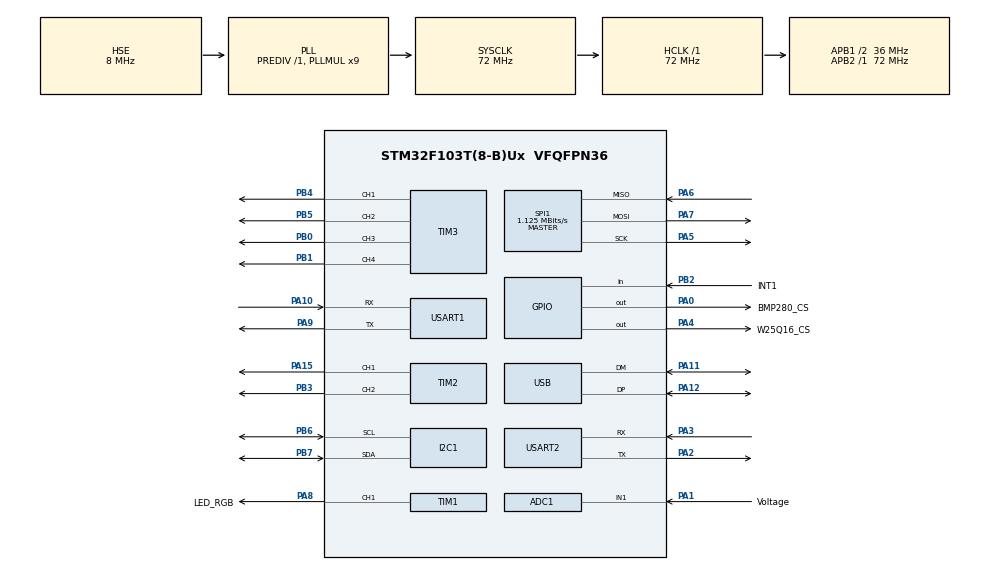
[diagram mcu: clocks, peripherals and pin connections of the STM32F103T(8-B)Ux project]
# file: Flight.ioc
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ADC1.Channel-1\#ChannelRegularConversion=ADC_CHANNEL_1
ADC1.NbrOfConversionFlag=1
ADC1.Rank-1\#ChannelRegularConversion=1
ADC1.SamplingTime-1\#ChannelRegularConversion=ADC_SAMPLETIME_1CYCLE_5
ADC1.master=1
Dma.Request0=TIM1_CH1
Dma.Request1=USART1_TX
Dma.TIM1_CH1.0.Direction=DMA_MEMORY_TO_PERIPH
Dma.TIM1_CH1.0.Instance=DMA1_Channel2
Dma.TIM1_CH1.0.MemDataAlignment=DMA_MDATAALIGN_HALFWORD
Dma.TIM1_CH1.0.MemInc=DMA_MINC_ENABLE
Dma.TIM1_CH1.0.Mode=DMA_NORMAL
Dma.TIM1_CH1.0.PeriphDataAlignment=DMA_PDATAALIGN_HALFWORD
Dma.TIM1_CH1.0.PeriphInc=DMA_PINC_DISABLE
Dma.TIM1_CH1.0.Priority=DMA_PRIORITY_VERY_HIGH
Dma.USART1_TX.1.Direction=DMA_MEMORY_TO_PERIPH
Dma.USART1_TX.1.Instance=DMA1_Channel4
Dma.USART1_TX.1.MemDataAlignment=DMA_MDATAALIGN_BYTE
Dma.USART1_TX.1.MemInc=DMA_MINC_ENABLE
Dma.USART1_TX.1.Mode=DMA_NORMAL
Dma.USART1_TX.1.PeriphDataAlignment=DMA_PDATAALIGN_BYTE
Dma.USART1_TX.1.PeriphInc=DMA_PINC_DISABLE
Dma.USART1_TX.1.Priority=DMA_PRIORITY_LOW
FREERTOS.Tasks01=mainTask,40,128,StartMainTask,Default,NULL,Dynamic,NULL,NULL
FREERTOS.configUSE_NEWLIB_REENTRANT=1
I2C1.I2C_Mode=I2C_Fast
Mcu.Family=STM32F1
Mcu.Name=STM32F103T(8-B)Ux
Mcu.Package=VFQFPN36
NVIC.DMA1_Channel2_IRQn=true\:5\:0\:false\:false\:true\:true\:false\:true\:true
NVIC.DMA1_Channel4_IRQn=true\:5\:0\:false\:false\:true\:true\:false\:true\:true
NVIC.PriorityGroup=NVIC_PRIORITYGROUP_4
NVIC.TIM4_IRQn=true\:15\:0\:false\:false\:true\:false\:false\:true\:true
NVIC.TimeBase=TIM4_IRQn
NVIC.TimeBaseIP=TIM4
NVIC.USART1_IRQn=true\:5\:0\:false\:false\:true\:true\:true\:true\:true
NVIC.USART2_IRQn=true\:5\:0\:false\:false\:true\:true\:true\:true\:true
PA0-WKUP.GPIO_Label=BMP280_CS
PA0-WKUP.GPIO_Speed=GPIO_SPEED_FREQ_HIGH
PA0-WKUP.PinState=GPIO_PIN_SET
PA0-WKUP.Signal=GPIO_Output
PA1.GPIO_Label=Voltage
PA1.Signal=SharedAnalog_PA1
PA10.Mode=Asynchronous
PA10.Signal=USART1_RX
PA11.Mode=Device
PA11.Signal=USB_DM
PA12.Mode=Device
PA12.Signal=USB_DP
PA13.Mode=Serial_Wire
PA13.Signal=SYS_JTMS-SWDIO
PA14.Mode=Serial_Wire
PA14.Signal=SYS_JTCK-SWCLK
PA15.Signal=S_TIM2_CH1_ETR
PA2.Mode=Asynchronous
PA2.Signal=USART2_TX
PA3.Mode=Asynchronous
PA3.Signal=USART2_RX
PA4.GPIO_Label=W25Q16_CS
PA4.GPIO_Speed=GPIO_SPEED_FREQ_HIGH
PA4.PinState=GPIO_PIN_SET
PA4.Signal=GPIO_Output
PA5.Mode=Full_Duplex_Master
PA5.Signal=SPI1_SCK
PA6.Mode=Full_Duplex_Master
PA6.Signal=SPI1_MISO
PA7.Mode=Full_Duplex_Master
PA7.Signal=SPI1_MOSI
PA8.GPIO_Label=LED_RGB
PA8.Signal=S_TIM1_CH1
PA9.Mode=Asynchronous
PA9.Signal=USART1_TX
PB0.Signal=S_TIM3_CH3
PB1.Signal=S_TIM3_CH4
PB2.GPIO_Label=INT1
PB2.Signal=GPIO_Input
PB3.Signal=S_TIM2_CH2
PB4.Signal=S_TIM3_CH1
PB5.Signal=S_TIM3_CH2
PB6.GPIO_Pu=GPIO_PULLUP
PB6.Mode=I2C
PB6.Signal=I2C1_SCL
PB7.GPIO_Pu=GPIO_PULLUP
PB7.Mode=I2C
PB7.Signal=I2C1_SDA
PD0-OSC_IN.Mode=HSE-External-Oscillator
PD0-OSC_IN.Signal=RCC_OSC_IN
PD1-OSC_OUT.Mode=HSE-External-Oscillator
PD1-OSC_OUT.Signal=RCC_OSC_OUT
ProjectManager.HeapSize=0x200
ProjectManager.StackSize=0x400
ProjectManager.TargetToolchain=STM32CubeIDE
RCC.ADCPresc=RCC_ADCPCLK2_DIV6
RCC.AHBFreq_Value=72000000
RCC.APB1CLKDivider=RCC_HCLK_DIV2
RCC.APB1Freq_Value=36000000
RCC.APB1TimFreq_Value=72000000
RCC.APB2Freq_Value=72000000
RCC.APB2TimFreq_Value=72000000
RCC.HCLKFreq_Value=72000000
RCC.PLLMUL=RCC_PLL_MUL9
RCC.SYSCLKFreq_VALUE=72000000
RCC.SYSCLKSource=RCC_SYSCLKSOURCE_PLLCLK
RCC.USBFreq_Value=48000000
RCC.USBPrescaler=RCC_USBCLKSOURCE_PLL_DIV1_5
SH.S_TIM1_CH1.0=TIM1_CH1,PWM Generation1 CH1
SH.S_TIM2_CH1_ETR.0=TIM2_CH1,PWM Generation1 CH1
SH.S_TIM2_CH2.0=TIM2_CH2,PWM Generation2 CH2
SH.S_TIM3_CH1.0=TIM3_CH1,PWM Generation1 CH1
SH.S_TIM3_CH2.0=TIM3_CH2,PWM Generation2 CH2
SH.S_TIM3_CH3.0=TIM3_CH3,PWM Generation3 CH3
SH.S_TIM3_CH4.0=TIM3_CH4,PWM Generation4 CH4
SH.SharedAnalog_PA1.0=GPIO_Analog
SH.SharedAnalog_PA1.1=ADC1_IN1,IN1
SPI1.BaudRatePrescaler=SPI_BAUDRATEPRESCALER_64
SPI1.CLKPhase=SPI_PHASE_2EDGE
SPI1.CLKPolarity=SPI_POLARITY_HIGH
SPI1.CalculateBaudRate=1.125 MBits/s
SPI1.Direction=SPI_DIRECTION_2LINES
SPI1.Mode=SPI_MODE_MASTER
SPI1.VirtualType=VM_MASTER
TIM1.Channel-PWM\ Generation1\ CH1=TIM_CHANNEL_1
TIM1.Period=90
TIM2.Channel-PWM\ Generation1\ CH1=TIM_CHANNEL_1
TIM2.Channel-PWM\ Generation2\ CH2=TIM_CHANNEL_2
TIM3.Channel-PWM\ Generation1\ CH1=TIM_CHANNEL_1
TIM3.Channel-PWM\ Generation2\ CH2=TIM_CHANNEL_2
TIM3.Channel-PWM\ Generation3\ CH3=TIM_CHANNEL_3
TIM3.Channel-PWM\ Generation4\ CH4=TIM_CHANNEL_4
USART1.VirtualMode=VM_ASYNC
USART2.VirtualMode=VM_ASYNC
VP_FATFS_VS_Generic.Mode=User_defined
VP_FREERTOS_VS_CMSIS_V2.Mode=CMSIS_V2
VP_IWDG_VS_IWDG.Mode=IWDG_Activate
VP_SYS_VS_tim4.Mode=TIM4
board=custom

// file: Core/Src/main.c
/* USER CODE BEGIN Header */
/**
  ******************************************************************************
  * @file           : main.c
  * @brief          : Main program body
  ******************************************************************************
  * @attention
  *
  * Copyright (c) 2023 STMicroelectronics.
  * All rights reserved.
  *
  * This software is licensed under terms that can be found in the LICENSE file
  * in the root directory of this software component.
  * If no LICENSE file comes with this software, it is provided AS-IS.
  *
  ******************************************************************************
  */
/* USER CODE END Header */
#include "main.h"
#include "cmsis_os.h"
#include "adc.h"
#include "dma.h"
#include "fatfs.h"
#include "i2c.h"
#include "iwdg.h"
#include "spi.h"
#include "tim.h"
#include "usart.h"
#include "usb.h"
#include "gpio.h"

void SystemClock_Config(void);
void MX_FREERTOS_Init(void);

int main(void)
{

  /* MCU Configuration--------------------------------------------------------*/

  /* Reset of all peripherals, Initializes the Flash interface and the Systick. */
  HAL_Init();

  /* Configure the system clock */
  SystemClock_Config();

  /* Initialize all configured peripherals */
  MX_GPIO_Init();
  MX_DMA_Init();
  MX_ADC1_Init();
  MX_I2C1_Init();
  MX_SPI1_Init();
  MX_USART1_UART_Init();
  MX_USART2_UART_Init();
  MX_TIM1_Init();
  MX_TIM2_Init();
  MX_TIM3_Init();
  MX_FATFS_Init();
  MX_IWDG_Init();
  // MX_USB_PCD_Init();

  /* Init scheduler */
  osKernelInitialize();  /* Call init function for freertos objects (in freertos.c) */
  MX_FREERTOS_Init();

  /* Start scheduler */
  osKernelStart();
  /* We should never get here as control is now taken by the scheduler */
  /* Infinite loop */
  while (1)
  {

  }
}

void SystemClock_Config(void)
{
  RCC_OscInitTypeDef RCC_OscInitStruct = {0};
  RCC_ClkInitTypeDef RCC_ClkInitStruct = {0};
  RCC_PeriphCLKInitTypeDef PeriphClkInit = {0};

  /** Initializes the RCC Oscillators according to the specified parameters
  * in the RCC_OscInitTypeDef structure.
  */
  RCC_OscInitStruct.OscillatorType = RCC_OSCILLATORTYPE_LSI|RCC_OSCILLATORTYPE_HSE;
  RCC_OscInitStruct.HSEState = RCC_HSE_ON;
  RCC_OscInitStruct.HSEPredivValue = RCC_HSE_PREDIV_DIV1;
  RCC_OscInitStruct.HSIState = RCC_HSI_ON;
  RCC_OscInitStruct.LSIState = RCC_LSI_ON;
  RCC_OscInitStruct.PLL.PLLState = RCC_PLL_ON;
  RCC_OscInitStruct.PLL.PLLSource = RCC_PLLSOURCE_HSE;
  RCC_OscInitStruct.PLL.PLLMUL = RCC_PLL_MUL9;
  if (HAL_RCC_OscConfig(&RCC_OscInitStruct) != HAL_OK)
  {
    Error_Handler();
  }

  /** Initializes the CPU, AHB and APB buses clocks
  */
  RCC_ClkInitStruct.ClockType = RCC_CLOCKTYPE_HCLK|RCC_CLOCKTYPE_SYSCLK
                              |RCC_CLOCKTYPE_PCLK1|RCC_CLOCKTYPE_PCLK2;
  RCC_ClkInitStruct.SYSCLKSource = RCC_SYSCLKSOURCE_PLLCLK;
  RCC_ClkInitStruct.AHBCLKDivider = RCC_SYSCLK_DIV1;
  RCC_ClkInitStruct.APB1CLKDivider = RCC_HCLK_DIV2;
  RCC_ClkInitStruct.APB2CLKDivider = RCC_HCLK_DIV1;

  if (HAL_RCC_ClockConfig(&RCC_ClkInitStruct, FLASH_LATENCY_2) != HAL_OK)
  {
    Error_Handler();
  }
  PeriphClkInit.PeriphClockSelection = RCC_PERIPHCLK_ADC|RCC_PERIPHCLK_USB;
  PeriphClkInit.AdcClockSelection = RCC_ADCPCLK2_DIV6;
  PeriphClkInit.UsbClockSelection = RCC_USBCLKSOURCE_PLL_DIV1_5;
  if (HAL_RCCEx_PeriphCLKConfig(&PeriphClkInit) != HAL_OK)
  {
    Error_Handler();
  }
}

void HAL_TIM_PeriodElapsedCallback(TIM_HandleTypeDef *htim)
{
  if (htim->Instance == TIM4) {
    HAL_IncTick();
  }
}

void Error_Handler(void)
{
  __disable_irq();
  while (1)
  {
  }
}

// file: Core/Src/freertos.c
/* USER CODE BEGIN Header */
/**
  ******************************************************************************
  * File Name          : freertos.c
  * Description        : Code for freertos applications
  ******************************************************************************
  * @attention
  *
  * Copyright (c) 2023 STMicroelectronics.
  * All rights reserved.
  *
  * This software is licensed under terms that can be found in the LICENSE file
  * in the root directory of this software component.
  * If no LICENSE file comes with this software, it is provided AS-IS.
  *
  ******************************************************************************
  */
/* USER CODE END Header */

#include "FreeRTOS.h"
#include "task.h"
#include "main.h"
#include "cmsis_os.h"

/* USER CODE BEGIN Includes */

#include "iwdg.h"
#include "usart.h"
#include "status_light.h"
#include "ws2812.h"
//#include "log.h"
#include "test.h"
#include "log.h"
#include "app_main.h"

/* USER CODE END Includes */

/* Definitions for mainTask */
osThreadId_t mainTaskHandle;
const osThreadAttr_t mainTask_attributes = {
  .name = "mainTask",
  .stack_size = 128 * 2,
  .priority = (osPriority_t) osPriorityHigh,
};

void StartMainTask(void *argument);

void MX_FREERTOS_Init(void); /* (MISRA C 2004 rule 8.1) */

void MX_FREERTOS_Init(void) {

  /* Create the thread(s) */
  /* creation of mainTask */
  mainTaskHandle = osThreadNew(StartMainTask, NULL, &mainTask_attributes);

  /* USER CODE BEGIN RTOS_THREADS */
  launch_app();
  // InitTest();

    /* add threads, ... */
  /* USER CODE END RTOS_THREADS */

}

void StartMainTask(void *argument)
{
  /* USER CODE BEGIN StartMainTask */

  // InitTest();

    /* Infinite loop */
  for(;;)
  {
    HAL_IWDG_Refresh(&hiwdg);
    vTaskDelay(10 / portTICK_PERIOD_MS);
  }
  /* USER CODE END StartMainTask */
}
